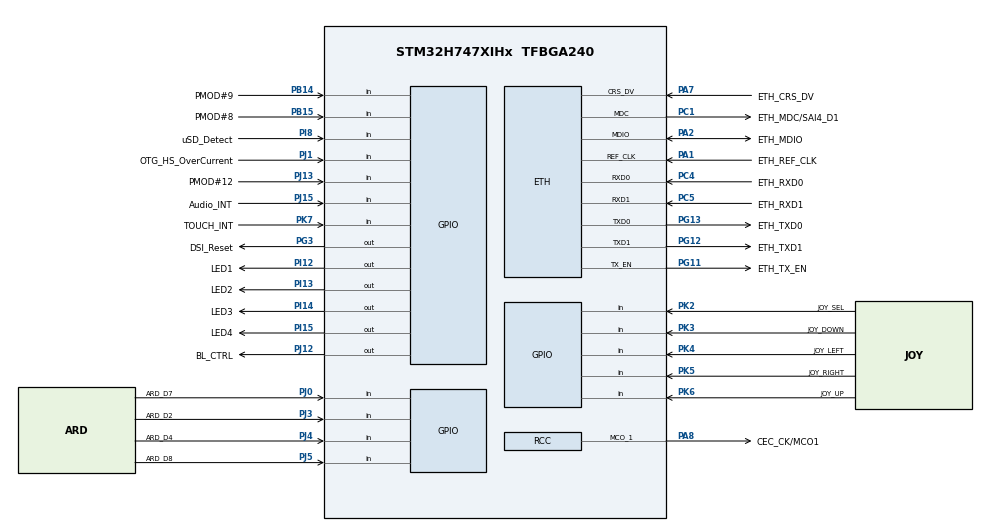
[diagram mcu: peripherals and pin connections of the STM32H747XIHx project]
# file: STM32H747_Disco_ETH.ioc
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NVIC1.TimeBaseIP=TIM6
SH.FMC_A0.0=FMC_A0
PH15.GPIO_Label=FMC_D23
PH0-OSC_IN\ (PH0).PinAttribute=CortexM7
PG8.Signal=FMC_SDCLK
LWIP.CHECKSUM_CHECK_ICMP=0
PG0.Signal=FMC_A10
CORTEX_M7.TypeExtField-Cortex_Memory_Protection_Unit_Region0_Settings=MPU_TEX_LEVEL1
PI15.GPIO_Label=LED4
PK1.Signal=SPI5_NSS
SH.FMC_D5_DA5.0=FMC_D5
SH.FMC_D9_DA9.0=FMC_D9
SH.FMC_D25.0=FMC_D25
CORTEX_M7.Enable-Cortex_Memory_Protection_Unit_Region0_Settings=MPU_REGION_ENABLE
CORTEX_M7.IsBufferable-Cortex_Memory_Protection_Unit_Region1_Settings=MPU_ACCESS_BUFFERABLE
PG15.GPIO_Label=FMC_SDCAS
PF7.Signal=QUADSPI_BK1_IO2
SH.FMC_SDNWE.0=FMC_SDNWE
PH9.Signal=FMC_D17
SH.FMC_D11_DA11.0=FMC_D11
PB6.Signal=CEC
PD0.Signal=FMC_D2_DA2
PD8.Signal=FMC_D13_DA13
PE1.Signal=FMC_NBL1
PF1.GPIO_Label=FMC_A1
PK4.GPIO_Label=JOY_LEFT
PI4.GPIO_Label=FMC_NBL2
PD1.GPIO_Label=FMC_D3
PB12.GPIO_Label=ULPI_D5
PF12.GPIO_Label=FMC_A6
PC4.GPIO_Label=ETH_RXD0
PE9.Signal=FMC_D6_DA6
SH.FMC_A2.0=FMC_A2
PB1.GPIO_Label=ULPI_D2
PI12.PinAttribute=Free
PE4.GPIO_Label=SAI1_FS_A
PG4.GPIO_Label=FMC_BA0
VP_SYS_M4_VS_Systick.Mode=SysTick
PA8.Signal=RCC_MCO_1
SH.FMC_D1_DA1.0=FMC_D1
PA7.PinAttribute=CortexM7
Mcu.Package=TFBGA240
PB1.Signal=USB_OTG_HS_ULPI_D2
PB15.PinAttribute=Free
PC3_C.GPIO_Label=ARD_A5
SH.FMC_D27.0=FMC_D27
PA10.Signal=USART1_RX
PE12.GPIO_Label=FMC_D9
PD15.Signal=FMC_D1_DA1
PJ1.GPIO_Label=OTG_HS_OverCurrent
PG12.Signal=ETH_TXD1
PG12.PinAttribute=CortexM7
PK4.Signal=GPIO_Input
SH.FMC_A4.0=FMC_A4
PH13.Signal=FMC_D21
LWIP0.BSP.i2caddr=0
PA1.PinAttribute=CortexM7
PA1_C.GPIO_Label=ARD_A3
PC13.Signal=RTC_TAMP1
SH.FMC_D10_DA10.0=FMC_D10
PC2.Signal=SPI2_MISO
PI12.Signal=GPIO_Output
SH.FMC_D16.0=FMC_D16
RCC.PWR_Regulator_Voltage_Scale=PWR_REGULATOR_VOLTAGE_SCALE1
PG13.PinAttribute=CortexM7
PJ11.Signal=SPI5_MISO
PF8.GPIO_Label=PMOD\#14/ARD_D3
PD10.Signal=FMC_D15_DA15
PJ8.GPIO_Label=ARD_D1
PJ3.Signal=GPIO_Input
PI8.GPIO_Label=uSD_Detect
PA8.GPIO_Label=CEC_CK/MCO1
SH.FMC_D29.0=FMC_D29
PA2.PinAttribute=CortexM7
PA0_C.GPIO_Label=ARD_A2
PE8.GPIO_Label=FMC_D5
PH11.GPIO_Label=FMC_D19
PJ11.GPIO_Label=ARD_D12
PB14.Signal=GPIO_Input
PA5.Signal=USB_OTG_HS_ULPI_CK
PG11.PinAttribute=CortexM7
PJ4.GPIO_Label=ARD_D4
PE1.GPIO_Label=FMC_NBL1
PK7.GPIO_Label=TOUCH_INT
PI7.Signal=FMC_D29
PC2_C.GPIO_Label=ARD_A4
SH.FMC_A6.0=FMC_A6
PE14.Signal=FMC_D11_DA11
PB15.GPIO_Label=PMOD\#8
PG7.GPIO_Label=SAI1_MCLK_A
PI2.Signal=FMC_D26
PF4.GPIO_Label=FMC_A4
PA1.GPIO_Label=ETH_REF_CLK
PC1.GPIO_Speed=GPIO_SPEED_FREQ_VERY_HIGH
PF13.Signal=FMC_A7
PJ15.GPIO_Label=Audio_INT
SH.FMC_NBL2.0=FMC_NBL2
SH.FMC_D18.0=FMC_D18
ETH.MediaInterface=HAL_ETH_RMII_MODE
PA8.PinAttribute=CortexM7
FREERTOS_M7.configMINIMAL_STACK_SIZE=256
PC14-OSC32_IN\ (OSC32_IN).GPIO_Label=OSC32_IN
PA5.GPIO_Label=ULPI_CK
PC12.GPIO_Label=SDIO1_CK
PE5.GPIO_Label=SAI1_SCK_A
PJ8.Signal=UART8_TX
PJ0.GPIO_Label=ARD_D7
ProjectManager.HeapSize=0x200
PH6.Signal=FMC_SDNE1
PG12.GPIO_Speed=GPIO_SPEED_FREQ_VERY_HIGH
PF0.GPIO_Label=FMC_A0
PC5.GPIO_Speed=GPIO_SPEED_FREQ_VERY_HIGH
PI11.GPIO_Label=ULPI_DIR
PE3.Signal=SAI1_SD_B
PF4.Signal=FMC_A4
PD2.Signal=SDMMC1_CMD
PC1.PinAttribute=CortexM7
PC1.Mode=RMII
PI1.GPIO_Label=FMC_D25
Mcu.Family=STM32H7
LWIP0.BSP.STBoard=false
PK3.Signal=GPIO_Input
SH.FMC_A8.0=FMC_A8
PH14.Signal=FMC_D22
PH10.Signal=FMC_D18
SH.FMC_D14_DA14.0=FMC_D14
PH0-OSC_IN\ (PH0).Signal=RCC_OSC_IN
PG2.Signal=FMC_A12
PE11.GPIO_Label=FMC_D8
PD0.GPIO_Label=FMC_D2
SH.FMC_A14_BA0.0=FMC_BA0
SH.FMC_A11.0=FMC_A11
PB13.GPIO_Label=ULPI_D6
PB15.Signal=GPIO_Input
PG15.Signal=FMC_SDNCAS
PG11.Signal=ETH_TX_EN
SH.S_TIM13_CH1.0=TIM13_CH1
PJ5.GPIO_Label=ARD_D8
SH.FMC_NBL1.0=FMC_NBL1
PA0_C.PinAttribute=CortexM4
PG11.GPIO_Speed=GPIO_SPEED_FREQ_VERY_HIGH
PC4.GPIO_Speed=GPIO_SPEED_FREQ_VERY_HIGH
NVIC2.PriorityGroup=NVIC_PRIORITYGROUP_4
PH7.GPIO_Label=FMC_SDCKE1
PJ7.GPIO_Label=ARD_D6
PF11.Signal=FMC_SDNRAS
PJ12.GPIO_Label=BL_CTRL
CortexM7.IPs=BDMA\:I,DMA\:I,FATFS_M7\:I,FREERTOS_M7\:I,IWDG1\:I,MDMA\:I,NVIC1\:I,RCC\:I,USB_DEVICE_M7\:I,USB_HOST_M7\:I,WWDG1\:I,CORTEX_M7\:I,DEBUG\:I,PDM2PCM_M7\:I,PWR\:I,RESMGR_UTILITY\:I,SYS\:I,OPENAMP_M7\:I,VREFBUF\:I,ETH\:I,LWIP\:I,TIM6\:I
LWIP0.BSP.solution=LAN8742
CORTEX_M7.DisableExec-Cortex_Memory_Protection_Unit_Region0_Settings=MPU_INSTRUCTION_ACCESS_DISABLE
PF8.Signal=S_TIM13_CH1
PG0.GPIO_Label=FMC_A10
PI0.GPIO_Label=FMC_D24
CORTEX_M7.Size-Cortex_Memory_Protection_Unit_Region1_Settings=MPU_REGION_SIZE_256B
PB5.GPIO_Label=ULPI_D7
PG11.GPIO_Label=ETH_TX_EN
PC5.Signal=ETH_RXD1
PE7.Signal=FMC_D4_DA4
PF3.GPIO_Label=FMC_A3
CORTEX_M7.IsShareable-Cortex_Memory_Protection_Unit_Region1_Settings=MPU_ACCESS_SHAREABLE
PG2.GPIO_Label=FMC_A12
PH1-OSC_OUT\ (PH1).PinAttribute=CortexM7
PA3.Signal=USB_OTG_HS_ULPI_D0
PH1-OSC_OUT\ (PH1).GPIO_Label=OSC_OUT
PB14.PinAttribute=Free
PK6.Signal=GPIO_Input
SH.FMC_D20.0=FMC_D20
PD15.GPIO_Label=FMC_D1
PG7.Signal=SAI1_MCLK_A
PA0_C.Signal=ADCx_INP0
PH12.GPIO_Label=FMC_D20
PI14.Signal=GPIO_Output
PI15.PinAttribute=Free
PC8.Signal=SDMMC1_D0
SH.FMC_D31.0=FMC_D31
PE14.GPIO_Label=FMC_D11
PD9.Signal=FMC_D14_DA14
PA12.GPIO_Label=SPI2_SCK
PH1-OSC_OUT\ (PH1).Signal=RCC_OSC_OUT
SH.ADCx_INP1.0=ADC1_INP1
PD8.GPIO_Label=FMC_D13
VP_FREERTOS_M7_VS_CMSIS_V2.Mode=CMSIS_V2
PG8.GPIO_Label=FMC_SDCLK
CORTEX_M7.MPU_Control=MPU_PRIVILEGED_DEFAULT
PF6.Signal=QUADSPI_BK1_IO3
PC15-OSC32_OUT\ (OSC32_OUT).Signal=RCC_OSC32_OUT
PB10.GPIO_Label=ULPI_D3
PI13.PinAttribute=Free
SH.FMC_D13_DA13.0=FMC_D13
PH8.Signal=FMC_D16
LWIP0.BSP.instance=LAN8742
RCC.USBFreq_Value=400000000
PF9.GPIO_Label=QSPI_BK1_IO1
PD10.GPIO_Label=FMC_D15
PA1.Signal=ETH_REF_CLK
board=STM32H747I-DISCO
PG12.Mode=RMII
PI9.Signal=FMC_D30
PH4.GPIO_Label=ULPI_NXT
SH.FMC_D22.0=FMC_D22
PI13.GPIO_Label=LED2
PK7.PinAttribute=Free
PI4.Signal=FMC_NBL2
PA1.GPIO_Speed=GPIO_SPEED_FREQ_VERY_HIGH
RCC.ADCFreq_Value=50390625
PC1.GPIO_Label=ETH_MDC/SAI4_D1
SH.FMC_D12_DA12.0=FMC_D12
PF15.GPIO_Label=FMC_A9
PF1.Signal=FMC_A1
NVIC1.TimeBase=TIM6_DAC_IRQn
PJ13.PinAttribute=Free
PJ0.Signal=GPIO_Input
PE0.Signal=FMC_NBL0
PE7.GPIO_Label=FMC_D4
PE12.Signal=FMC_D9_DA9
RCC.SYSCLKFreq_VALUE=400000000
PC15-OSC32_OUT\ (OSC32_OUT).GPIO_Label=OSC32_OUT
PJ5.Signal=GPIO_Input
PB2.GPIO_Label=QSPI_CLK
PI3.GPIO_Label=FMC_D27
PH0-OSC_IN\ (PH0).GPIO_Label=OSC_IN
PH3.Signal=QUADSPI_BK2_IO1
PC3_C.Signal=ADC3_INP1
PA2.Mode=RMII
PC5.PinAttribute=CortexM7
CORTEX_M7.CPU_DCache=Enabled
LWIP0.BSP.name=Driver_PHY
PB12.Signal=USB_OTG_HS_ULPI_D5
PJ13.Signal=GPIO_Input
PK1.GPIO_Label=ARD_D10
PA3.GPIO_Label=ULPI_D0
CortexM4.IPs=BDMA,DMA,FATFS_M4\:I,FREERTOS_M4\:I,IWDG2\:I,MDMA,NVIC2\:I,RCC,USB_DEVICE_M4\:I,USB_HOST_M4\:I,WWDG2\:I,DCMI\:I,DEBUG,PDM2PCM_M4\:I,PWR,RESMGR_UTILITY,SYS_M4\:I,CORTEX_M4\:I,OPENAMP_M4\:I,VREFBUF
SH.FMC_D7_DA7.0=FMC_D7
PK5.Signal=GPIO_Input
VP_SYS_VS_tim6.Mode=TIM6
SH.FMC_D24.0=FMC_D24
PH12.Signal=FMC_D20
PK5.PinAttribute=Free
PG4.Signal=FMC_A14_BA0
PC12.Signal=SDMMC1_CK
PB14.GPIO_Label=PMOD\#9
PG6.GPIO_Label=QSPI_BK1_NCS
PH6.GPIO_Label=FMC_SDNE1
PK6.GPIO_Label=JOY_UP
PJ4.PinAttribute=Free
PJ3.PinAttribute=Free
PI6.GPIO_Label=FMC_D28
PB6.GPIO_Label=HDMI_CEC
PJ6.GPIO_Label=ARD_D9
PJ12.PinAttribute=Free
PC5.Mode=RMII
PB13.Signal=USB_OTG_HS_ULPI_D6
LWIP.CHECKSUM_GEN_ICMP=0
PG13.Signal=ETH_TXD0
PE6.GPIO_Label=SAI1_SD_A
PF6.GPIO_Label=QSPI_BK1_IO3
RCC.SYSCLKSource=RCC_SYSCLKSOURCE_PLLCLK
PJ10.Signal=SPI5_MOSI
LWIP.NETMASK_ADDRESS=255.255.255.000
PJ13.GPIO_Label=PMOD\#12
PK6.PinAttribute=Free
PH5.Signal=FMC_SDNWE
PK4.PinAttribute=Free
PC3.Signal=SPI2_MOSI
PE5.Signal=SAI1_SCK_A
PF10.GPIO_Label=ARD_A1
PH10.GPIO_Label=FMC_D18
PB2.Signal=QUADSPI_CLK
RCC.DIVM1=5
SH.FMC_D26.0=FMC_D26
PI6.Signal=FMC_D28
PI3.Signal=FMC_D27
PJ1.PinAttribute=Free
PF3.Signal=FMC_A3
PJ5.PinAttribute=Free
PE10.Signal=FMC_D7_DA7
CORTEX_M7.DisableExec-Cortex_Memory_Protection_Unit_Region1_Settings=MPU_INSTRUCTION_ACCESS_DISABLE
PJ4.Signal=GPIO_Input
SH.FMC_A1.0=FMC_A1
PH2.Signal=QUADSPI_BK2_IO0
SH.FMC_SDCLK.0=FMC_SDCLK
RCC.APB4Freq_Value=100000000
FREERTOS_M7.Tasks01=defaultTask,24,256,StartDefaultTask,Default,NULL,Dynamic,NULL,NULL
PF14.Signal=FMC_A8
CORTEX_M7.Enable-Cortex_Memory_Protection_Unit_Region1_Settings=MPU_REGION_ENABLE
PI11.Signal=USB_OTG_HS_ULPI_DIR
PE10.GPIO_Label=FMC_D7
PH0-OSC_IN\ (PH0).Mode=HSE-External-Clock-Source
SH.FMC_D3_DA3.0=FMC_D3
RCC.SupplySource=PWR_DIRECT_SMPS_SUPPLY
PC4.Mode=RMII
LWIP.IP_ADDRESS=192.168.001.010
PI10.GPIO_Label=FMC_D31
PH15.Signal=FMC_D23
SH.FMC_D28.0=FMC_D28
PD9.GPIO_Label=FMC_D14
PG9.Signal=QUADSPI_BK2_IO2
PA9.GPIO_Label=STLINK_RX
PB11.GPIO_Label=ULPI_D4
PD7.Signal=SPDIFRX1_IN0
PD1.Signal=FMC_D3_DA3
PA11.GPIO_Label=PMOD\#1
PF14.GPIO_Label=FMC_A8
LWIP.LWIP_DHCP=0
PC0.Signal=USB_OTG_HS_ULPI_STP
PF13.GPIO_Label=FMC_A7
PG13.GPIO_Label=ETH_TXD0
PJ15.PinAttribute=Free
SH.S_TIM8_CH2.0=TIM8_CH2
SH.FMC_A3.0=FMC_A3
PJ7.Signal=TIM8_CH2N
PK2.PinAttribute=Free
SH.FMC_D15_DA15.0=FMC_D15
PA9.Signal=USART1_TX
RCC.DIVN1=160
CORTEX_M7.BaseAddress-Cortex_Memory_Protection_Unit_Region0_Settings=0x30040000
PE9.GPIO_Label=FMC_D6
SH.FMC_D17.0=FMC_D17
PB10.Signal=USB_OTG_HS_ULPI_D3
PG3.PinAttribute=Free
PJ15.Signal=GPIO_Input
PH9.GPIO_Label=FMC_D17
PI9.GPIO_Label=FMC_D30
PA7.GPIO_Speed=GPIO_SPEED_FREQ_VERY_HIGH
PK3.PinAttribute=Free
PA1.Mode=RMII
PE15.Signal=FMC_D12_DA12
PE8.Signal=FMC_D5_DA5
PI1.Signal=FMC_D25
CORTEX_M7.AccessPermission-Cortex_Memory_Protection_Unit_Region0_Settings=MPU_REGION_FULL_ACCESS
SH.FMC_SDNCAS.0=FMC_SDNCAS
PG14.GPIO_Label=QSPI_BK2_IO3
RCC.ProductRev=revV
PH14.GPIO_Label=FMC_D22
PB5.Signal=USB_OTG_HS_ULPI_D7
PE13.GPIO_Label=FMC_D10
PD11.Signal=QUADSPI_BK1_IO0
SH.FMC_A5.0=FMC_A5
PG11.Mode=RMII
PA11.Signal=SPI2_NSS
PK3.GPIO_Label=JOY_DOWN
LWIP.Version=v2.1.2_Cube
PF9.Signal=QUADSPI_BK1_IO1
PC3.GPIO_Label=PMOD\#2
PA8.Mode=Clock-out-1
SH.FMC_NBL3.0=FMC_NBL3
PG3.GPIO_Label=DSI_Reset
PA1_C.PinAttribute=CortexM4
PB0.Signal=USB_OTG_HS_ULPI_D1
SH.FMC_D19.0=FMC_D19
PC1.Signal=ETH_MDC
PD2.GPIO_Label=SDIO1_CMD
PH2.GPIO_Label=QSPI_BK2_IO0
PK7.Signal=GPIO_Input
RCC.CortexFreq_Value=400000000
PG6.Signal=QUADSPI_BK1_NCS
RCC.HPRE=RCC_HCLK_DIV2
PC10.Signal=SDMMC1_D2
PA1_C.Signal=ADCx_INP1
SH.FMC_NBL0.0=FMC_NBL0
PA2.GPIO_Speed=GPIO_SPEED_FREQ_VERY_HIGH
PC0.GPIO_Label=ULPI_STP
SH.FMC_D6_DA6.0=FMC_D6
PB0.GPIO_Label=ULPI_D1
PI5.GPIO_Label=FMC_NBL3
PH5.GPIO_Label=FMC_SDNWE
PC13.GPIO_Label=B2 [Wakeup Button]
PK5.GPIO_Label=JOY_RIGHT
PB11.Signal=USB_OTG_HS_ULPI_D4
PI14.GPIO_Label=LED3
ProjectManager.StackSize=0x400
PJ6.Signal=S_TIM8_CH2
SH.FMC_A7.0=FMC_A7
PA12.Signal=SPI2_SCK
PD11.GPIO_Label=QSPI_BK1_IO0
RCC.HCLKFreq_Value=200000000
PF11.GPIO_Label=FMC_SDRAS
PF12.Signal=FMC_A6
PI13.Signal=GPIO_Output
PC2_C.Signal=ADC3_INP0
SH.FMC_A10.0=FMC_A10
SH.FMC_D8_DA8.0=FMC_D8
PI8.Signal=GPIO_Input
SH.FMC_D2_DA2.0=FMC_D2
PE13.Signal=FMC_D10_DA10
PF7.GPIO_Label=QSPI_BK1_IO2
PI5.Signal=FMC_NBL3
PI0.Signal=FMC_D24
PI8.PinAttribute=Free
PA10.GPIO_Label=STLINK_TX
PG13.Mode=RMII
SH.FMC_SDNRAS.0=FMC_SDNRAS
PE4.Signal=SAI1_FS_A
PD7.GPIO_Label=SPDIF_RX0
RCC.APB3Freq_Value=100000000
LWIP0.BSP.component=LAN8742
PJ9.Signal=UART8_RX
SH.FMC_D0_DA0.0=FMC_D0
RCC.D1PPRE=RCC_APB3_DIV2
PJ12.Signal=GPIO_Output
CORTEX_M7.BaseAddress-Cortex_Memory_Protection_Unit_Region1_Settings=0x30040000
PK0.GPIO_Label=ARD_D13
PA2.GPIO_Label=ETH_MDIO
PF5.GPIO_Label=FMC_A5
SH.FMC_A9.0=FMC_A9
PJ1.Signal=GPIO_Input
SH.FMC_D4_DA4.0=FMC_D4
PI12.GPIO_Label=LED1
PE0.GPIO_Label=FMC_NBL0
PF5.Signal=FMC_A5
PH3.GPIO_Label=QSPI_BK2_IO1
PH7.Signal=FMC_SDCKE1
PJ3.GPIO_Label=ARD_D2
PK2.GPIO_Label=JOY_SEL
SH.FMC_D30.0=FMC_D30
PG13.GPIO_Speed=GPIO_SPEED_FREQ_VERY_HIGH
PF0.Signal=FMC_A0
PI2.GPIO_Label=FMC_D26
PC2.GPIO_Label=PMOD\#3
SH.FMC_A12.0=FMC_A12
RCC.PLLSourceVirtual=RCC_PLLSOURCE_HSE
PK2.Signal=GPIO_Input
CORTEX_M7.CPU_ICache=Enabled
NVIC1.TIM6_DAC_IRQn=true\:0\:0\:false\:false\:true\:false\:false\:true
PA7.Mode=RMII
PC10.GPIO_Label=SDIO1_D2
PH11.Signal=FMC_D19
PG3.Signal=GPIO_Output
PG1.Signal=FMC_A11
PJ0.PinAttribute=Free
PI14.PinAttribute=Free
PC4.Signal=ETH_RXD0
NVIC1.PriorityGroup=NVIC_PRIORITYGROUP_4
RCC.D2PPRE2=RCC_APB2_DIV2
RCC.D2PPRE1=RCC_APB1_DIV2
PI10.Signal=FMC_D31
VP_LWIP_VS_Enabled.Mode=Enabled
LWIP.GATEWAY_ADDRESS=192.168.001.001
NVIC1.ETH_IRQn=true\:5\:0\:false\:false\:true\:true\:true\:true
PH13.GPIO_Label=FMC_D21
PC8.GPIO_Label=SDIO1_D0
SH.FMC_D21.0=FMC_D21
PH8.GPIO_Label=FMC_D16
PE15.GPIO_Label=FMC_D12
PH4.Signal=USB_OTG_HS_ULPI_NXT
ProjectManager.TargetToolchain=STM32CubeIDE
PC14-OSC32_IN\ (OSC32_IN).PinAttribute=CortexM7
PJ9.GPIO_Label=ARD_D0
PF2.Signal=FMC_A2
PC4.PinAttribute=CortexM7
PE11.Signal=FMC_D8_DA8
LWIP0.BSP.api=BSP_COMPONENT_DRIVER
PK0.Signal=SPI5_SCK
PG9.GPIO_Label=QSPI_BK2_IO2
PG14.Signal=QUADSPI_BK2_IO3
SH.ADCx_INP0.0=ADC1_INP0
PJ10.GPIO_Label=ARD_D11
PG1.GPIO_Label=FMC_A11
RCC.APB2Freq_Value=100000000
PF10.Signal=ADC3_INP6
PI7.GPIO_Label=FMC_D29
PF15.Signal=FMC_A9
PD14.GPIO_Label=FMC_D0
PE6.Signal=SAI1_SD_A
Mcu.Name=STM32H747XIHx
CORTEX_M7.Size-Cortex_Memory_Protection_Unit_Region0_Settings=MPU_REGION_SIZE_32KB
PA2.Signal=ETH_MDIO
CORTEX_M7.AccessPermission-Cortex_Memory_Protection_Unit_Region1_Settings=MPU_REGION_FULL_ACCESS
PD14.Signal=FMC_D0_DA0
PA7.GPIO_Label=ETH_CRS_DV
LWIP.BSP.number=1
PC14-OSC32_IN\ (OSC32_IN).Signal=RCC_OSC32_IN
PC5.GPIO_Label=ETH_RXD1
SH.FMC_D23.0=FMC_D23
PG12.GPIO_Label=ETH_TXD1
PI15.Signal=GPIO_Output
PC15-OSC32_OUT\ (OSC32_OUT).PinAttribute=CortexM7
PE3.GPIO_Label=SAI1_SD_B
RCC.D3PPRE=RCC_APB4_DIV2
RCC.APB1Freq_Value=100000000
PA7.Signal=ETH_CRS_DV
PF2.GPIO_Label=FMC_A2

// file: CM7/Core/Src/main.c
/* USER CODE BEGIN Header */
/**
  ******************************************************************************
  * @file           : main.c
  * @brief          : Main program body
  ******************************************************************************
  * @attention
  *
  * <h2><center>&copy; Copyright (c) 2021 STMicroelectronics.
  * All rights reserved.</center></h2>
  *
  * This software component is licensed by ST under Ultimate Liberty license
  * SLA0044, the "License"; You may not use this file except in compliance with
  * the License. You may obtain a copy of the License at:
  *                             www.st.com/SLA0044
  *
  ******************************************************************************
  */
/* USER CODE END Header */
#include "main.h"
#include "cmsis_os.h"
#include "lwip.h"

/* USER CODE BEGIN PD */

#ifndef HSEM_ID_0
#define HSEM_ID_0 (0U) /* HW semaphore 0*/
#endif
/* USER CODE END PD */

/* Definitions for defaultTask */
osThreadId_t defaultTaskHandle;
const osThreadAttr_t defaultTask_attributes = {
  .name = "defaultTask",
  .stack_size = 256 * 4,
  .priority = (osPriority_t) osPriorityNormal,
};

void SystemClock_Config(void);
static void MPU_Config(void);
static void MX_GPIO_Init(void);
void StartDefaultTask(void *argument);

int main(void)
{
/* USER CODE BEGIN Boot_Mode_Sequence_0 */

/* USER CODE END Boot_Mode_Sequence_0 */

  /* MPU Configuration--------------------------------------------------------*/
  MPU_Config();

  /* Enable I-Cache---------------------------------------------------------*/
  SCB_EnableICache();

  /* Enable D-Cache---------------------------------------------------------*/
  SCB_EnableDCache();

/* USER CODE BEGIN Boot_Mode_Sequence_1 */

/* USER CODE END Boot_Mode_Sequence_1 */
  /* MCU Configuration--------------------------------------------------------*/

  /* Reset of all peripherals, Initializes the Flash interface and the Systick. */
  HAL_Init();

  /* Configure the system clock */
  SystemClock_Config();
/* USER CODE BEGIN Boot_Mode_Sequence_2 */

/* USER CODE END Boot_Mode_Sequence_2 */

  /* Initialize all configured peripherals */
  MX_GPIO_Init();
  /* USER CODE BEGIN 2 */
  __HAL_RCC_HSEM_CLK_ENABLE();
  HAL_HSEM_FastTake(HSEM_ID_0);
  HAL_HSEM_Release(HSEM_ID_0,0);
  /* USER CODE END 2 */

  /* Init scheduler */
  osKernelInitialize();

  /* Create the thread(s) */
  /* creation of defaultTask */
  defaultTaskHandle = osThreadNew(StartDefaultTask, NULL, &defaultTask_attributes);

  /* Start scheduler */
  osKernelStart();

  /* We should never get here as control is now taken by the scheduler */
  /* Infinite loop */
  while (1)
  {

  }
}

void SystemClock_Config(void)
{
  RCC_OscInitTypeDef RCC_OscInitStruct = {0};
  RCC_ClkInitTypeDef RCC_ClkInitStruct = {0};

  /** Supply configuration update enable
  */
  HAL_PWREx_ConfigSupply(PWR_DIRECT_SMPS_SUPPLY);
  /** Configure the main internal regulator output voltage
  */
  __HAL_PWR_VOLTAGESCALING_CONFIG(PWR_REGULATOR_VOLTAGE_SCALE1);

  while(!__HAL_PWR_GET_FLAG(PWR_FLAG_VOSRDY)) {}
  /** Initializes the RCC Oscillators according to the specified parameters
  * in the RCC_OscInitTypeDef structure.
  */
  RCC_OscInitStruct.OscillatorType = RCC_OSCILLATORTYPE_HSI|RCC_OSCILLATORTYPE_HSE;
  RCC_OscInitStruct.HSEState = RCC_HSE_BYPASS;
  RCC_OscInitStruct.HSIState = RCC_HSI_DIV1;
  RCC_OscInitStruct.HSICalibrationValue = RCC_HSICALIBRATION_DEFAULT;
  RCC_OscInitStruct.PLL.PLLState = RCC_PLL_ON;
  RCC_OscInitStruct.PLL.PLLSource = RCC_PLLSOURCE_HSE;
  RCC_OscInitStruct.PLL.PLLM = 5;
  RCC_OscInitStruct.PLL.PLLN = 160;
  RCC_OscInitStruct.PLL.PLLP = 2;
  RCC_OscInitStruct.PLL.PLLQ = 2;
  RCC_OscInitStruct.PLL.PLLR = 2;
  RCC_OscInitStruct.PLL.PLLRGE = RCC_PLL1VCIRANGE_2;
  RCC_OscInitStruct.PLL.PLLVCOSEL = RCC_PLL1VCOWIDE;
  RCC_OscInitStruct.PLL.PLLFRACN = 0;
  if (HAL_RCC_OscConfig(&RCC_OscInitStruct) != HAL_OK)
  {
    Error_Handler();
  }
  /** Initializes the CPU, AHB and APB buses clocks
  */
  RCC_ClkInitStruct.ClockType = RCC_CLOCKTYPE_HCLK|RCC_CLOCKTYPE_SYSCLK
                              |RCC_CLOCKTYPE_PCLK1|RCC_CLOCKTYPE_PCLK2
                              |RCC_CLOCKTYPE_D3PCLK1|RCC_CLOCKTYPE_D1PCLK1;
  RCC_ClkInitStruct.SYSCLKSource = RCC_SYSCLKSOURCE_PLLCLK;
  RCC_ClkInitStruct.SYSCLKDivider = RCC_SYSCLK_DIV1;
  RCC_ClkInitStruct.AHBCLKDivider = RCC_HCLK_DIV2;
  RCC_ClkInitStruct.APB3CLKDivider = RCC_APB3_DIV2;
  RCC_ClkInitStruct.APB1CLKDivider = RCC_APB1_DIV2;
  RCC_ClkInitStruct.APB2CLKDivider = RCC_APB2_DIV2;
  RCC_ClkInitStruct.APB4CLKDivider = RCC_APB4_DIV2;

  if (HAL_RCC_ClockConfig(&RCC_ClkInitStruct, FLASH_LATENCY_2) != HAL_OK)
  {
    Error_Handler();
  }
  HAL_RCC_MCOConfig(RCC_MCO1, RCC_MCO1SOURCE_HSI, RCC_MCODIV_1);
}

static void MX_GPIO_Init(void)
{
  GPIO_InitTypeDef GPIO_InitStruct = {0};

  /* GPIO Ports Clock Enable */
  __HAL_RCC_GPIOG_CLK_ENABLE();
  __HAL_RCC_GPIOC_CLK_ENABLE();
  __HAL_RCC_GPIOA_CLK_ENABLE();
  __HAL_RCC_GPIOH_CLK_ENABLE();

  /*Configure GPIO pin : CEC_CK_MCO1_Pin */
  GPIO_InitStruct.Pin = CEC_CK_MCO1_Pin;
  GPIO_InitStruct.Mode = GPIO_MODE_AF_PP;
  GPIO_InitStruct.Pull = GPIO_NOPULL;
  GPIO_InitStruct.Speed = GPIO_SPEED_FREQ_LOW;
  GPIO_InitStruct.Alternate = GPIO_AF0_MCO;
  HAL_GPIO_Init(CEC_CK_MCO1_GPIO_Port, &GPIO_InitStruct);

}

void StartDefaultTask(void *argument)
{
  /* init code for LWIP */
  MX_LWIP_Init();
  for(;;)
  {
    osDelay(1);
  }
}

/* MPU Configuration */

void MPU_Config(void)
{
  MPU_Region_InitTypeDef MPU_InitStruct = {0};

  /* Disables the MPU */
  HAL_MPU_Disable();
  /** Initializes and configures the Region and the memory to be protected
  */
  MPU_InitStruct.Enable = MPU_REGION_ENABLE;
  MPU_InitStruct.Number = MPU_REGION_NUMBER0;
  MPU_InitStruct.BaseAddress = 0x30040000;
  MPU_InitStruct.Size = MPU_REGION_SIZE_32KB;
  MPU_InitStruct.SubRegionDisable = 0x0;
  MPU_InitStruct.TypeExtField = MPU_TEX_LEVEL1;
  MPU_InitStruct.AccessPermission = MPU_REGION_FULL_ACCESS;
  MPU_InitStruct.DisableExec = MPU_INSTRUCTION_ACCESS_DISABLE;
  MPU_InitStruct.IsShareable = MPU_ACCESS_NOT_SHAREABLE;
  MPU_InitStruct.IsCacheable = MPU_ACCESS_NOT_CACHEABLE;
  MPU_InitStruct.IsBufferable = MPU_ACCESS_NOT_BUFFERABLE;

  HAL_MPU_ConfigRegion(&MPU_InitStruct);
  /** Initializes and configures the Region and the memory to be protected
  */
  MPU_InitStruct.Number = MPU_REGION_NUMBER1;
  MPU_InitStruct.Size = MPU_REGION_SIZE_256B;
  MPU_InitStruct.TypeExtField = MPU_TEX_LEVEL0;
  MPU_InitStruct.IsShareable = MPU_ACCESS_SHAREABLE;
  MPU_InitStruct.IsBufferable = MPU_ACCESS_BUFFERABLE;

  HAL_MPU_ConfigRegion(&MPU_InitStruct);
  /* Enables the MPU */
  HAL_MPU_Enable(MPU_PRIVILEGED_DEFAULT);

}
void HAL_TIM_PeriodElapsedCallback(TIM_HandleTypeDef *htim)
{
  if (htim->Instance == TIM6) {
    HAL_IncTick();
  }
}

void Error_Handler(void)
{
  __disable_irq();
  while (1)
  {
  }
}

/************************ (C) COPYRIGHT STMicroelectronics *****END OF FILE****/
